VERSION ""

NS_ :

BS_:

BU_: BMS Charger

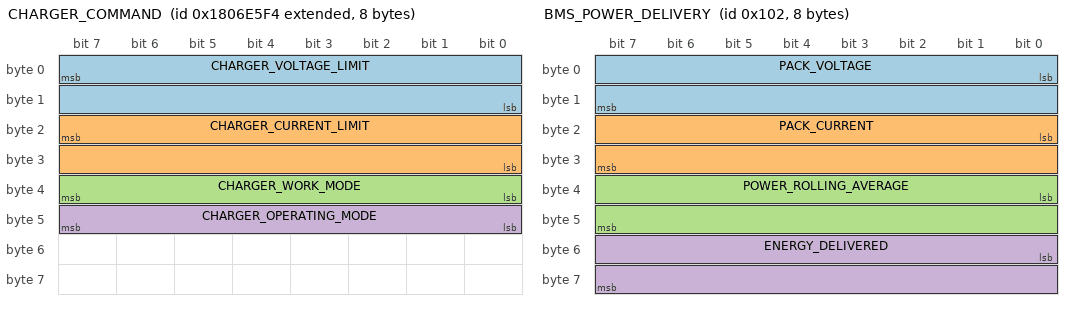
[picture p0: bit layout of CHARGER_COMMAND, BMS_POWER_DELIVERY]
BO_ 2550588916 CHARGER_COMMAND: 8 BMS
 SG_ CHARGER_VOLTAGE_LIMIT : 7|16@0+ (0.1,0) [0|680] "V" Vector__XXX
 SG_ CHARGER_CURRENT_LIMIT : 23|16@0+ (0.1,0) [0|14] "A" Vector__XXX
 SG_ CHARGER_WORK_MODE : 39|8@0+ (1,0) [0|2] "Enum" Vector__XXX
 SG_ CHARGER_OPERATING_MODE : 47|8@0+ (1,0) [0|0] "Enum" Vector__XXX

BO_ 2566869221 CHARGER_RESPONSE: 8 Charger
 SG_ CHARGE_VOLTGE_OUTPUT : 7|16@0+ (0.1,0) [0|680] "V" Vector__XXX
 SG_ CHARGER_CURRENT_OUTPUT : 23|16@0+ (0.1,0) [0|14] "A" Vector__XXX
 SG_ CHARGER_HARDWARE_PROTECTION : 32|1@0+ (1,0) [0|1] "Bool" Vector__XXX
 SG_ CHARGER_TEMPERATURE_PROTECTION : 33|1@0+ (1,0) [0|1] "Bool" Vector__XXX
 SG_ CHARGER_INPUT_VOLTAGE_STATUS : 35|2@0+ (1,0) [0|1] "Bool" Vector__XXX
 SG_ CHARGER_OUTPUT_UNDERVOLTAGE : 36|1@0+ (1,0) [0|1] "Bool" Vector__XXX
 SG_ CHARGER_OUTPUT_OVERVOLTAGE : 37|1@0+ (1,0) [0|1] "Bool" Vector__XXX
 SG_ CHARGE__OUTPUT_OVERCURRENT : 38|1@0+ (1,0) [0|1] "Bool" Vector__XXX
 SG_ CHARGER_OUTPUT_SHORT_CIRCUIT : 39|1@0+ (1,0) [0|1] "Bool" Vector__XXX
 SG_ CHARGER_COMMAND_FAULT : 40|1@0+ (1,0) [0|1] "Bool" Vector__XXX
 SG_ CHARGER_WORK_STATUS : 42|2@0+ (1,0) [0|3] "Enum" Vector__XXX
 SG_ CHARGER_INITIALIZED : 43|1@0+ (1,0) [0|1] "Bool" Vector__XXX
 SG_ CHARGER_FAN_ENABLED : 44|1@0+ (1,0) [0|1] "Bool" Vector__XXX
 SG_ CHARGER_COOLING_PUMP_ENABLED : 45|1@0+ (1,0) [0|1] "Bool" Vector__XXX
 SG_ CHARGER_CC_STATUS : 49|2@0+ (1,0) [0|3] "Enum" Vector__XXX
 SG_ CHARGER_CP_STATUS : 50|1@0+ (1,0) [0|1] "Bool" Vector__XXX
 SG_ CHARGER_SOCKET_OVERTEMPERATURE : 51|1@0+ (1,0) [0|1] "Bool" Vector__XXX
 SG_ CHARGER_ELECTRONIC_LOCK : 54|3@0+ (1,0) [0|4] "Enum" Vector__XXX
 SG_ CHARGER_S2_SWITCH_CONTROL : 55|1@0+ (1,0) [0|1] "Bool" Vector__XXX
 SG_ CHARGER_TEMPERATURE : 63|8@0+ (1,-40) [-40|205] "C" Vector__XXX

BO_ 257 BMS_STATUS: 6 BMS
 SG_ BMS_UNDERVOLTAGE_FAULT : 0|1@1+ (1,0) [0|1] "Bool" Vector__XXX
 SG_ BMS_OVERVOLTAGE_FAULT : 1|1@1+ (1,0) [0|1] "Bool" Vector__XXX
 SG_ BMS_UNDERTEMPERATURE_FAULT : 2|1@1+ (1,0) [0|1] "Bool" Vector__XXX
 SG_ BMS_OVERTEMPERATURE_FAULT : 3|1@1+ (1,0) [0|1] "Bool" Vector__XXX
 SG_ BMS_SENSE_LINE_FAULT : 4|1@1+ (1,0) [0|1] "Bool" Vector__XXX
 SG_ BMS_ISOSPI_FAULT : 5|1@1+ (1,0) [0|1] "Bool" Vector__XXX
 SG_ BMS_SELF_TEST_FAULT : 6|1@1+ (1,0) [0|1] "Bool" Vector__XXX
 SG_ BMS_LTC_0_ISOSPI_FAULT : 16|1@1+ (1,0) [0|1] "Bool" Vector__XXX
 SG_ BMS_LTC_1_ISOSPI_FAULT : 17|1@1+ (1,0) [0|1] "Bool" Vector__XXX
 SG_ BMS_LTC_2_ISOSPI_FAULT : 18|1@1+ (1,0) [0|1] "Bool" Vector__XXX
 SG_ BMS_LTC_3_ISOSPI_FAULT : 19|1@1+ (1,0) [0|1] "Bool" Vector__XXX
 SG_ BMS_LTC_4_ISOSPI_FAULT : 20|1@1+ (1,0) [0|1] "Bool" Vector__XXX
 SG_ BMS_LTC_5_ISOSPI_FAULT : 21|1@1+ (1,0) [0|1] "Bool" Vector__XXX
 SG_ BMS_LTC_6_ISOSPI_FAULT : 22|1@1+ (1,0) [0|1] "Bool" Vector__XXX
 SG_ BMS_LTC_7_ISOSPI_FAULT : 23|1@1+ (1,0) [0|1] "Bool" Vector__XXX
 SG_ BMS_LTC_8_ISOSPI_FAULT : 24|1@1+ (1,0) [0|1] "Bool" Vector__XXX
 SG_ BMS_LTC_9_ISOSPI_FAULT : 25|1@1+ (1,0) [0|1] "Bool" Vector__XXX
 SG_ BMS_LTC_10_ISOSPI_FAULT : 26|1@1+ (1,0) [0|1] "Bool" Vector__XXX
 SG_ BMS_LTC_11_ISOSPI_FAULT : 27|1@1+ (1,0) [0|1] "Bool" Vector__XXX
 SG_ BMS_LTC_0_SELF_TEST_FAULT : 32|1@1+ (1,0) [0|1] "Bool" Vector__XXX
 SG_ BMS_LTC_1_SELF_TEST_FAULT : 33|1@1+ (1,0) [0|1] "Bool" Vector__XXX
 SG_ BMS_LTC_2_SELF_TEST_FAULT : 34|1@1+ (1,0) [0|1] "Bool" Vector__XXX
 SG_ BMS_LTC_3_SELF_TEST_FAULT : 35|1@1+ (1,0) [0|1] "Bool" Vector__XXX
 SG_ BMS_LTC_4_SELF_TEST_FAULT : 36|1@1+ (1,0) [0|1] "Bool" Vector__XXX
 SG_ BMS_LTC_5_SELF_TEST_FAULT : 37|1@1+ (1,0) [0|1] "Bool" Vector__XXX
 SG_ BMS_LTC_6_SELF_TEST_FAULT : 38|1@1+ (1,0) [0|1] "Bool" Vector__XXX
 SG_ BMS_LTC_7_SELF_TEST_FAULT : 39|1@1+ (1,0) [0|1] "Bool" Vector__XXX
 SG_ BMS_LTC_8_SELF_TEST_FAULT : 40|1@1+ (1,0) [0|1] "Bool" Vector__XXX
 SG_ BMS_LTC_9_SELF_TEST_FAULT : 41|1@1+ (1,0) [0|1] "Bool" Vector__XXX
 SG_ BMS_LTC_10_SELF_TEST_FAULT : 42|1@1+ (1,0) [0|1] "Bool" Vector__XXX
 SG_ BMS_LTC_11_SELF_TEST_FAULT : 43|1@1+ (1,0) [0|1] "Bool" Vector__XXX
 SG_ BMS_CHARGING : 7|1@1+ (1,0) [0|1] "Bool" Vector__XXX
 SG_ BMS_BALANCING : 8|1@1+ (1,0) [0|1] "Bool" Vector__XXX
 SG_ SHUTDOWN_CLOSED : 9|1@1+ (1,0) [0|1] "Bool" Vector__XXX
 SG_ PRECHARGE_COMPLETE : 10|1@1+ (1,0) [0|1] "Bool" Vector__XXX
 SG_ SHUTDOWN_LOOP_BLIP : 11|1@1+ (1,0) [0|1] "Bool" Vector__XXX
 SG_ BMS_RELAY_STATUS : 12|1@1+ (1,0) [0|1] "Bool" Vector__XXX
 SG_ IMD_RELAY_STATUS : 13|1@1+ (1,0) [0|1] "Bool" Vector__XXX
 SG_ BMS_FAULT : 14|1@1+ (1,0) [0|0] "Bool" Vector__XXX

BO_ 258 BMS_POWER_DELIVERY: 8 BMS
 SG_ PACK_VOLTAGE : 0|16@1+ (0.0125,0) [0|819.2] "V" Vector__XXX
 SG_ PACK_CURRENT : 16|16@1- (0.019073486328125,0) [-625|625] "A" Vector__XXX
 SG_ POWER_ROLLING_AVERAGE : 32|16@1- (0.004,0) [-131.072|131.068] "kW" Vector__XXX
 SG_ ENERGY_DELIVERED : 48|16@1- (0.0005,0) [-16.384|16.3835] "kWh" Vector__XXX

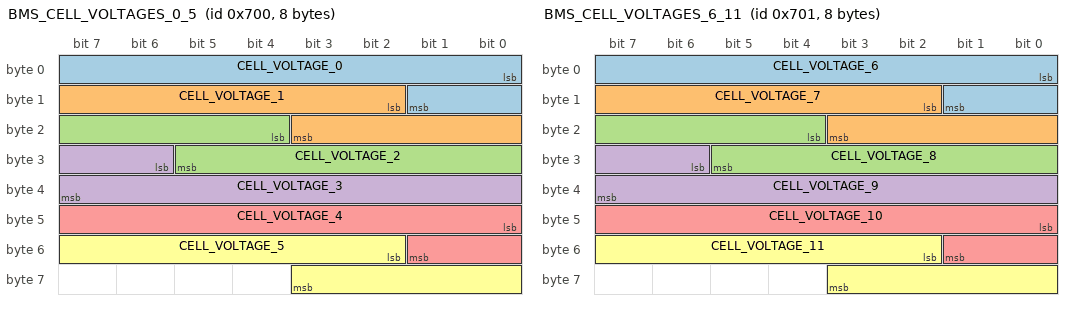
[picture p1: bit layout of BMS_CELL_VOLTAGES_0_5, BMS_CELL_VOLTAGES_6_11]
BO_ 1792 BMS_CELL_VOLTAGES_0_5: 8 BMS
 SG_ CELL_VOLTAGE_0 : 0|10@1+ (0.0078125,0) [0|8] "V" Vector__XXX
 SG_ CELL_VOLTAGE_1 : 10|10@1+ (0.0078125,0) [0|8] "V" Vector__XXX
 SG_ CELL_VOLTAGE_2 : 20|10@1+ (0.0078125,0) [0|8] "V" Vector__XXX
 SG_ CELL_VOLTAGE_3 : 30|10@1+ (0.0078125,0) [0|8] "V" Vector__XXX
 SG_ CELL_VOLTAGE_4 : 40|10@1+ (0.0078125,0) [0|8] "V" Vector__XXX
 SG_ CELL_VOLTAGE_5 : 50|10@1+ (0.0078125,0) [0|8] "V" Vector__XXX

BO_ 1793 BMS_CELL_VOLTAGES_6_11: 8 BMS
 SG_ CELL_VOLTAGE_6 : 0|10@1+ (0.0078125,0) [0|8] "V" Vector__XXX
 SG_ CELL_VOLTAGE_7 : 10|10@1+ (0.0078125,0) [0|8] "V" Vector__XXX
 SG_ CELL_VOLTAGE_8 : 20|10@1+ (0.0078125,0) [0|8] "V" Vector__XXX
 SG_ CELL_VOLTAGE_9 : 30|10@1+ (0.0078125,0) [0|8] "V" Vector__XXX
 SG_ CELL_VOLTAGE_10 : 40|10@1+ (0.0078125,0) [0|8] "V" Vector__XXX
 SG_ CELL_VOLTAGE_11 : 50|10@1+ (0.0078125,0) [0|8] "V" Vector__XXX

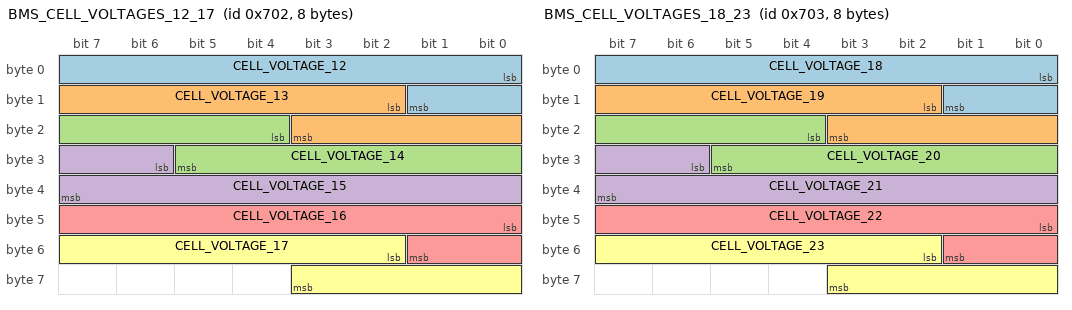
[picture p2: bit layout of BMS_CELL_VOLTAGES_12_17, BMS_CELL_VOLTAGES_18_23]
BO_ 1794 BMS_CELL_VOLTAGES_12_17: 8 BMS
 SG_ CELL_VOLTAGE_12 : 0|10@1+ (0.0078125,0) [0|8] "V" Vector__XXX
 SG_ CELL_VOLTAGE_13 : 10|10@1+ (0.0078125,0) [0|8] "V" Vector__XXX
 SG_ CELL_VOLTAGE_14 : 20|10@1+ (0.0078125,0) [0|8] "V" Vector__XXX
 SG_ CELL_VOLTAGE_15 : 30|10@1+ (0.0078125,0) [0|8] "V" Vector__XXX
 SG_ CELL_VOLTAGE_16 : 40|10@1+ (0.0078125,0) [0|8] "V" Vector__XXX
 SG_ CELL_VOLTAGE_17 : 50|10@1+ (0.0078125,0) [0|8] "V" Vector__XXX

BO_ 1795 BMS_CELL_VOLTAGES_18_23: 8 BMS
 SG_ CELL_VOLTAGE_18 : 0|10@1+ (0.0078125,0) [0|8] "V" Vector__XXX
 SG_ CELL_VOLTAGE_19 : 10|10@1+ (0.0078125,0) [0|8] "V" Vector__XXX
 SG_ CELL_VOLTAGE_20 : 20|10@1+ (0.0078125,0) [0|8] "V" Vector__XXX
 SG_ CELL_VOLTAGE_21 : 30|10@1+ (0.0078125,0) [0|8] "V" Vector__XXX
 SG_ CELL_VOLTAGE_22 : 40|10@1+ (0.0078125,0) [0|8] "V" Vector__XXX
 SG_ CELL_VOLTAGE_23 : 50|10@1+ (0.0078125,0) [0|8] "V" Vector__XXX

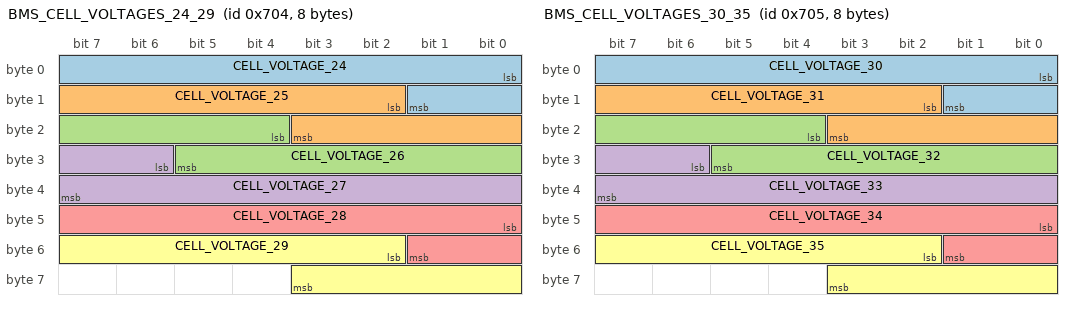
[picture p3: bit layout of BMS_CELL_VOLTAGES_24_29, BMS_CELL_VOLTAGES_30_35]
BO_ 1796 BMS_CELL_VOLTAGES_24_29: 8 BMS
 SG_ CELL_VOLTAGE_24 : 0|10@1+ (0.0078125,0) [0|8] "V" Vector__XXX
 SG_ CELL_VOLTAGE_25 : 10|10@1+ (0.0078125,0) [0|8] "V" Vector__XXX
 SG_ CELL_VOLTAGE_26 : 20|10@1+ (0.0078125,0) [0|8] "V" Vector__XXX
 SG_ CELL_VOLTAGE_27 : 30|10@1+ (0.0078125,0) [0|8] "V" Vector__XXX
 SG_ CELL_VOLTAGE_28 : 40|10@1+ (0.0078125,0) [0|8] "V" Vector__XXX
 SG_ CELL_VOLTAGE_29 : 50|10@1+ (0.0078125,0) [0|8] "V" Vector__XXX

BO_ 1797 BMS_CELL_VOLTAGES_30_35: 8 BMS
 SG_ CELL_VOLTAGE_30 : 0|10@1+ (0.0078125,0) [0|8] "V" Vector__XXX
 SG_ CELL_VOLTAGE_31 : 10|10@1+ (0.0078125,0) [0|8] "V" Vector__XXX
 SG_ CELL_VOLTAGE_32 : 20|10@1+ (0.0078125,0) [0|8] "V" Vector__XXX
 SG_ CELL_VOLTAGE_33 : 30|10@1+ (0.0078125,0) [0|8] "V" Vector__XXX
 SG_ CELL_VOLTAGE_34 : 40|10@1+ (0.0078125,0) [0|8] "V" Vector__XXX
 SG_ CELL_VOLTAGE_35 : 50|10@1+ (0.0078125,0) [0|8] "V" Vector__XXX

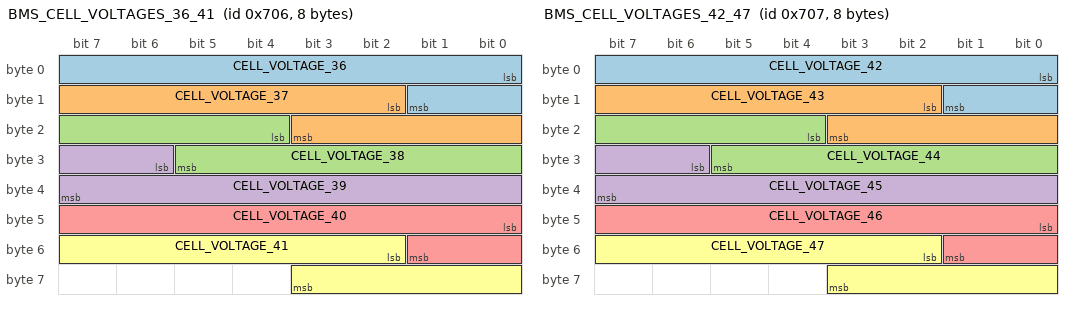
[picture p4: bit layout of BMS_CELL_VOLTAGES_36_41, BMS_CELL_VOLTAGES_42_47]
BO_ 1798 BMS_CELL_VOLTAGES_36_41: 8 BMS
 SG_ CELL_VOLTAGE_36 : 0|10@1+ (0.0078125,0) [0|8] "V" Vector__XXX
 SG_ CELL_VOLTAGE_37 : 10|10@1+ (0.0078125,0) [0|8] "V" Vector__XXX
 SG_ CELL_VOLTAGE_38 : 20|10@1+ (0.0078125,0) [0|8] "V" Vector__XXX
 SG_ CELL_VOLTAGE_39 : 30|10@1+ (0.0078125,0) [0|8] "V" Vector__XXX
 SG_ CELL_VOLTAGE_40 : 40|10@1+ (0.0078125,0) [0|8] "V" Vector__XXX
 SG_ CELL_VOLTAGE_41 : 50|10@1+ (0.0078125,0) [0|8] "V" Vector__XXX

BO_ 1799 BMS_CELL_VOLTAGES_42_47: 8 BMS
 SG_ CELL_VOLTAGE_42 : 0|10@1+ (0.0078125,0) [0|8] "V" Vector__XXX
 SG_ CELL_VOLTAGE_43 : 10|10@1+ (0.0078125,0) [0|8] "V" Vector__XXX
 SG_ CELL_VOLTAGE_44 : 20|10@1+ (0.0078125,0) [0|8] "V" Vector__XXX
 SG_ CELL_VOLTAGE_45 : 30|10@1+ (0.0078125,0) [0|8] "V" Vector__XXX
 SG_ CELL_VOLTAGE_46 : 40|10@1+ (0.0078125,0) [0|8] "V" Vector__XXX
 SG_ CELL_VOLTAGE_47 : 50|10@1+ (0.0078125,0) [0|8] "V" Vector__XXX

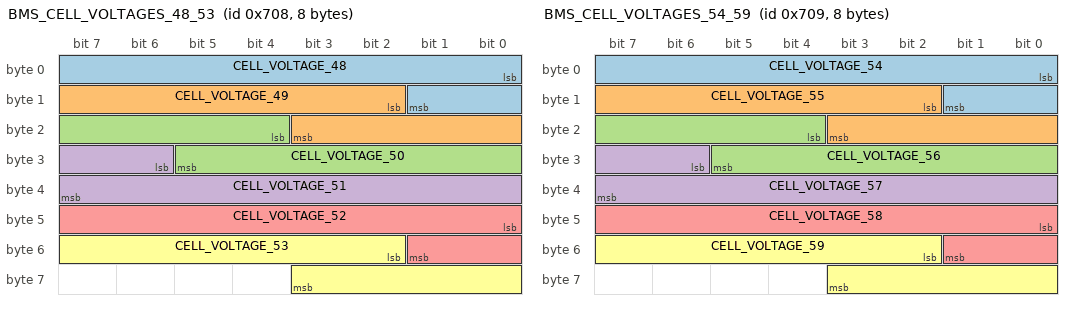
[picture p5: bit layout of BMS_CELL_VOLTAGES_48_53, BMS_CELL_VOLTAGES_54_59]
BO_ 1800 BMS_CELL_VOLTAGES_48_53: 8 BMS
 SG_ CELL_VOLTAGE_48 : 0|10@1+ (0.0078125,0) [0|8] "V" Vector__XXX
 SG_ CELL_VOLTAGE_49 : 10|10@1+ (0.0078125,0) [0|8] "V" Vector__XXX
 SG_ CELL_VOLTAGE_50 : 20|10@1+ (0.0078125,0) [0|8] "V" Vector__XXX
 SG_ CELL_VOLTAGE_51 : 30|10@1+ (0.0078125,0) [0|8] "V" Vector__XXX
 SG_ CELL_VOLTAGE_52 : 40|10@1+ (0.0078125,0) [0|8] "V" Vector__XXX
 SG_ CELL_VOLTAGE_53 : 50|10@1+ (0.0078125,0) [0|8] "V" Vector__XXX

BO_ 1801 BMS_CELL_VOLTAGES_54_59: 8 BMS
 SG_ CELL_VOLTAGE_54 : 0|10@1+ (0.0078125,0) [0|8] "V" Vector__XXX
 SG_ CELL_VOLTAGE_55 : 10|10@1+ (0.0078125,0) [0|8] "V" Vector__XXX
 SG_ CELL_VOLTAGE_56 : 20|10@1+ (0.0078125,0) [0|8] "V" Vector__XXX
 SG_ CELL_VOLTAGE_57 : 30|10@1+ (0.0078125,0) [0|8] "V" Vector__XXX
 SG_ CELL_VOLTAGE_58 : 40|10@1+ (0.0078125,0) [0|8] "V" Vector__XXX
 SG_ CELL_VOLTAGE_59 : 50|10@1+ (0.0078125,0) [0|8] "V" Vector__XXX

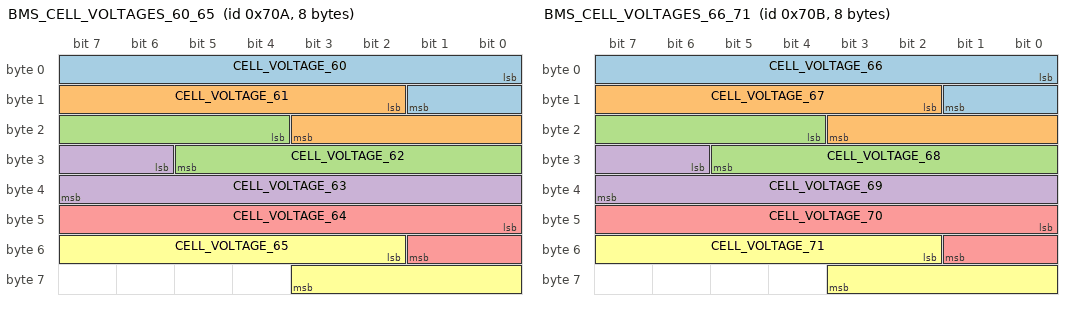
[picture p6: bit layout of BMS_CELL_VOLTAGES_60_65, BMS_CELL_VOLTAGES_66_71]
BO_ 1802 BMS_CELL_VOLTAGES_60_65: 8 BMS
 SG_ CELL_VOLTAGE_60 : 0|10@1+ (0.0078125,0) [0|8] "V" Vector__XXX
 SG_ CELL_VOLTAGE_61 : 10|10@1+ (0.0078125,0) [0|8] "V" Vector__XXX
 SG_ CELL_VOLTAGE_62 : 20|10@1+ (0.0078125,0) [0|8] "V" Vector__XXX
 SG_ CELL_VOLTAGE_63 : 30|10@1+ (0.0078125,0) [0|8] "V" Vector__XXX
 SG_ CELL_VOLTAGE_64 : 40|10@1+ (0.0078125,0) [0|8] "V" Vector__XXX
 SG_ CELL_VOLTAGE_65 : 50|10@1+ (0.0078125,0) [0|8] "V" Vector__XXX

BO_ 1803 BMS_CELL_VOLTAGES_66_71: 8 BMS
 SG_ CELL_VOLTAGE_66 : 0|10@1+ (0.0078125,0) [0|8] "V" Vector__XXX
 SG_ CELL_VOLTAGE_67 : 10|10@1+ (0.0078125,0) [0|8] "V" Vector__XXX
 SG_ CELL_VOLTAGE_68 : 20|10@1+ (0.0078125,0) [0|8] "V" Vector__XXX
 SG_ CELL_VOLTAGE_69 : 30|10@1+ (0.0078125,0) [0|8] "V" Vector__XXX
 SG_ CELL_VOLTAGE_70 : 40|10@1+ (0.0078125,0) [0|8] "V" Vector__XXX
 SG_ CELL_VOLTAGE_71 : 50|10@1+ (0.0078125,0) [0|8] "V" Vector__XXX

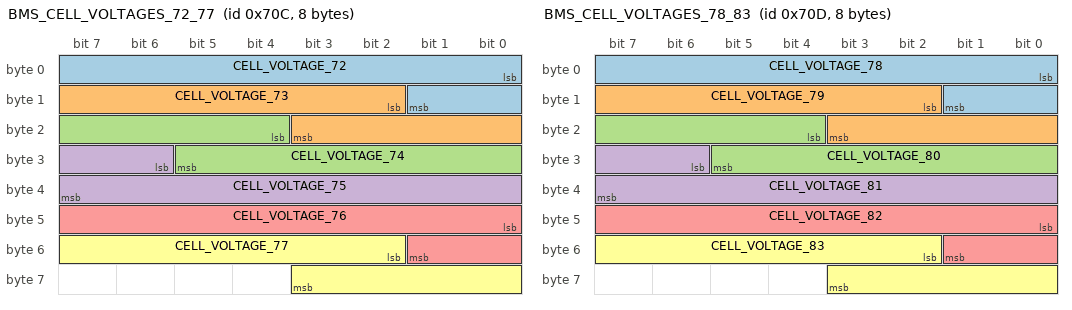
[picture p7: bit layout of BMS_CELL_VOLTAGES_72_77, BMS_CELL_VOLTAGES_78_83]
BO_ 1804 BMS_CELL_VOLTAGES_72_77: 8 BMS
 SG_ CELL_VOLTAGE_72 : 0|10@1+ (0.0078125,0) [0|8] "V" Vector__XXX
 SG_ CELL_VOLTAGE_73 : 10|10@1+ (0.0078125,0) [0|8] "V" Vector__XXX
 SG_ CELL_VOLTAGE_74 : 20|10@1+ (0.0078125,0) [0|8] "V" Vector__XXX
 SG_ CELL_VOLTAGE_75 : 30|10@1+ (0.0078125,0) [0|8] "V" Vector__XXX
 SG_ CELL_VOLTAGE_76 : 40|10@1+ (0.0078125,0) [0|8] "V" Vector__XXX
 SG_ CELL_VOLTAGE_77 : 50|10@1+ (0.0078125,0) [0|8] "V" Vector__XXX

BO_ 1805 BMS_CELL_VOLTAGES_78_83: 8 BMS
 SG_ CELL_VOLTAGE_78 : 0|10@1+ (0.0078125,0) [0|8] "V" Vector__XXX
 SG_ CELL_VOLTAGE_79 : 10|10@1+ (0.0078125,0) [0|8] "V" Vector__XXX
 SG_ CELL_VOLTAGE_80 : 20|10@1+ (0.0078125,0) [0|8] "V" Vector__XXX
 SG_ CELL_VOLTAGE_81 : 30|10@1+ (0.0078125,0) [0|8] "V" Vector__XXX
 SG_ CELL_VOLTAGE_82 : 40|10@1+ (0.0078125,0) [0|8] "V" Vector__XXX
 SG_ CELL_VOLTAGE_83 : 50|10@1+ (0.0078125,0) [0|8] "V" Vector__XXX

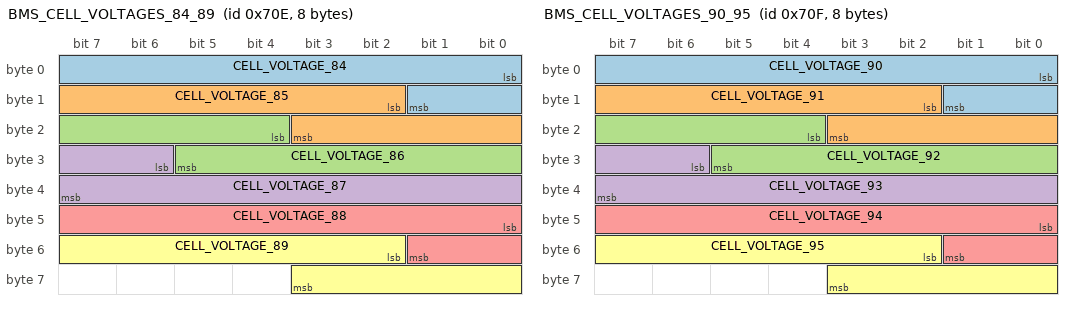
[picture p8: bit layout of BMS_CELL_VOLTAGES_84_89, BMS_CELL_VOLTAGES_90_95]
BO_ 1806 BMS_CELL_VOLTAGES_84_89: 8 BMS
 SG_ CELL_VOLTAGE_84 : 0|10@1+ (0.0078125,0) [0|8] "V" Vector__XXX
 SG_ CELL_VOLTAGE_85 : 10|10@1+ (0.0078125,0) [0|8] "V" Vector__XXX
 SG_ CELL_VOLTAGE_86 : 20|10@1+ (0.0078125,0) [0|8] "V" Vector__XXX
 SG_ CELL_VOLTAGE_87 : 30|10@1+ (0.0078125,0) [0|8] "V" Vector__XXX
 SG_ CELL_VOLTAGE_88 : 40|10@1+ (0.0078125,0) [0|8] "V" Vector__XXX
 SG_ CELL_VOLTAGE_89 : 50|10@1+ (0.0078125,0) [0|8] "V" Vector__XXX

BO_ 1807 BMS_CELL_VOLTAGES_90_95: 8 BMS
 SG_ CELL_VOLTAGE_90 : 0|10@1+ (0.0078125,0) [0|8] "V" Vector__XXX
 SG_ CELL_VOLTAGE_91 : 10|10@1+ (0.0078125,0) [0|8] "V" Vector__XXX
 SG_ CELL_VOLTAGE_92 : 20|10@1+ (0.0078125,0) [0|8] "V" Vector__XXX
 SG_ CELL_VOLTAGE_93 : 30|10@1+ (0.0078125,0) [0|8] "V" Vector__XXX
 SG_ CELL_VOLTAGE_94 : 40|10@1+ (0.0078125,0) [0|8] "V" Vector__XXX
 SG_ CELL_VOLTAGE_95 : 50|10@1+ (0.0078125,0) [0|8] "V" Vector__XXX

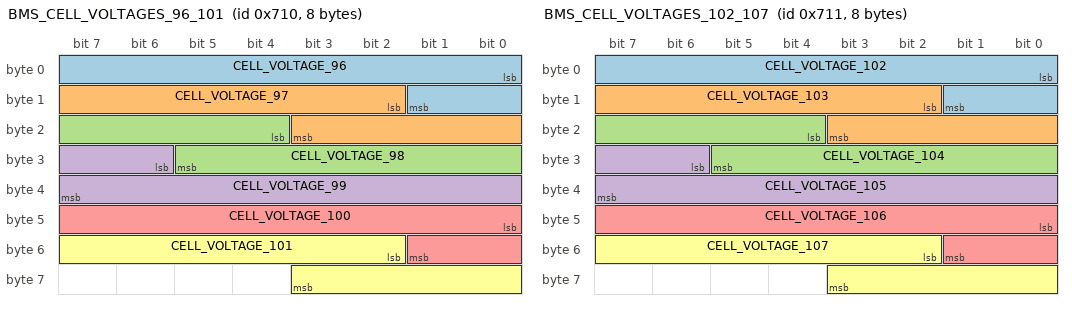
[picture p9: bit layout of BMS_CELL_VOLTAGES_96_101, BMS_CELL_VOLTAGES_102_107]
BO_ 1808 BMS_CELL_VOLTAGES_96_101: 8 BMS
 SG_ CELL_VOLTAGE_96 : 0|10@1+ (0.0078125,0) [0|8] "V" Vector__XXX
 SG_ CELL_VOLTAGE_97 : 10|10@1+ (0.0078125,0) [0|8] "V" Vector__XXX
 SG_ CELL_VOLTAGE_98 : 20|10@1+ (0.0078125,0) [0|8] "V" Vector__XXX
 SG_ CELL_VOLTAGE_99 : 30|10@1+ (0.0078125,0) [0|8] "V" Vector__XXX
 SG_ CELL_VOLTAGE_100 : 40|10@1+ (0.0078125,0) [0|8] "V" Vector__XXX
 SG_ CELL_VOLTAGE_101 : 50|10@1+ (0.0078125,0) [0|8] "V" Vector__XXX

BO_ 1809 BMS_CELL_VOLTAGES_102_107: 8 BMS
 SG_ CELL_VOLTAGE_102 : 0|10@1+ (0.0078125,0) [0|8] "V" Vector__XXX
 SG_ CELL_VOLTAGE_103 : 10|10@1+ (0.0078125,0) [0|8] "V" Vector__XXX
 SG_ CELL_VOLTAGE_104 : 20|10@1+ (0.0078125,0) [0|8] "V" Vector__XXX
 SG_ CELL_VOLTAGE_105 : 30|10@1+ (0.0078125,0) [0|8] "V" Vector__XXX
 SG_ CELL_VOLTAGE_106 : 40|10@1+ (0.0078125,0) [0|8] "V" Vector__XXX
 SG_ CELL_VOLTAGE_107 : 50|10@1+ (0.0078125,0) [0|8] "V" Vector__XXX

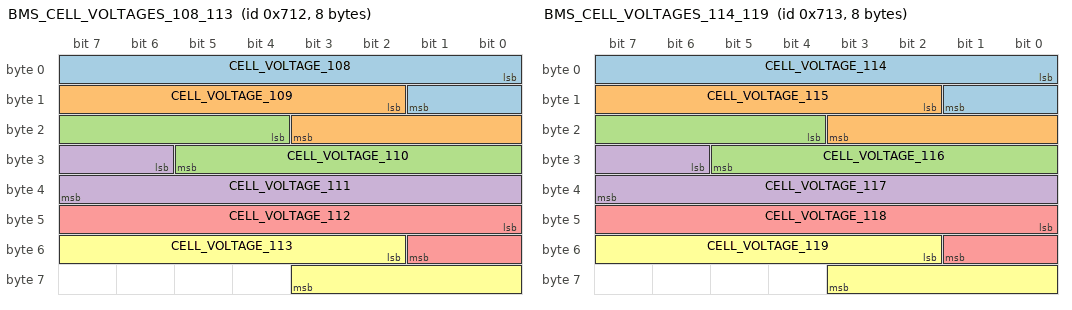
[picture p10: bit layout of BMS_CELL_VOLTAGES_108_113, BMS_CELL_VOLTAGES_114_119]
BO_ 1810 BMS_CELL_VOLTAGES_108_113: 8 BMS
 SG_ CELL_VOLTAGE_108 : 0|10@1+ (0.0078125,0) [0|8] "V" Vector__XXX
 SG_ CELL_VOLTAGE_109 : 10|10@1+ (0.0078125,0) [0|8] "V" Vector__XXX
 SG_ CELL_VOLTAGE_110 : 20|10@1+ (0.0078125,0) [0|8] "V" Vector__XXX
 SG_ CELL_VOLTAGE_111 : 30|10@1+ (0.0078125,0) [0|8] "V" Vector__XXX
 SG_ CELL_VOLTAGE_112 : 40|10@1+ (0.0078125,0) [0|8] "V" Vector__XXX
 SG_ CELL_VOLTAGE_113 : 50|10@1+ (0.0078125,0) [0|8] "V" Vector__XXX

BO_ 1811 BMS_CELL_VOLTAGES_114_119: 8 BMS
 SG_ CELL_VOLTAGE_114 : 0|10@1+ (0.0078125,0) [0|8] "V" Vector__XXX
 SG_ CELL_VOLTAGE_115 : 10|10@1+ (0.0078125,0) [0|8] "V" Vector__XXX
 SG_ CELL_VOLTAGE_116 : 20|10@1+ (0.0078125,0) [0|8] "V" Vector__XXX
 SG_ CELL_VOLTAGE_117 : 30|10@1+ (0.0078125,0) [0|8] "V" Vector__XXX
 SG_ CELL_VOLTAGE_118 : 40|10@1+ (0.0078125,0) [0|8] "V" Vector__XXX
 SG_ CELL_VOLTAGE_119 : 50|10@1+ (0.0078125,0) [0|8] "V" Vector__XXX

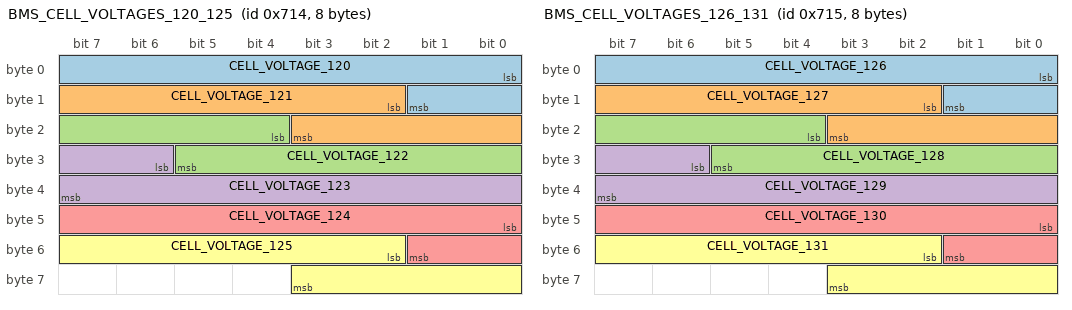
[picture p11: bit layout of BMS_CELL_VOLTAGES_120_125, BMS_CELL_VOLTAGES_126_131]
BO_ 1812 BMS_CELL_VOLTAGES_120_125: 8 BMS
 SG_ CELL_VOLTAGE_120 : 0|10@1+ (0.0078125,0) [0|8] "V" Vector__XXX
 SG_ CELL_VOLTAGE_121 : 10|10@1+ (0.0078125,0) [0|8] "V" Vector__XXX
 SG_ CELL_VOLTAGE_122 : 20|10@1+ (0.0078125,0) [0|8] "V" Vector__XXX
 SG_ CELL_VOLTAGE_123 : 30|10@1+ (0.0078125,0) [0|8] "V" Vector__XXX
 SG_ CELL_VOLTAGE_124 : 40|10@1+ (0.0078125,0) [0|8] "V" Vector__XXX
 SG_ CELL_VOLTAGE_125 : 50|10@1+ (0.0078125,0) [0|8] "V" Vector__XXX

BO_ 1813 BMS_CELL_VOLTAGES_126_131: 8 BMS
 SG_ CELL_VOLTAGE_126 : 0|10@1+ (0.0078125,0) [0|8] "V" Vector__XXX
 SG_ CELL_VOLTAGE_127 : 10|10@1+ (0.0078125,0) [0|8] "V" Vector__XXX
 SG_ CELL_VOLTAGE_128 : 20|10@1+ (0.0078125,0) [0|8] "V" Vector__XXX
 SG_ CELL_VOLTAGE_129 : 30|10@1+ (0.0078125,0) [0|8] "V" Vector__XXX
 SG_ CELL_VOLTAGE_130 : 40|10@1+ (0.0078125,0) [0|8] "V" Vector__XXX
 SG_ CELL_VOLTAGE_131 : 50|10@1+ (0.0078125,0) [0|8] "V" Vector__XXX

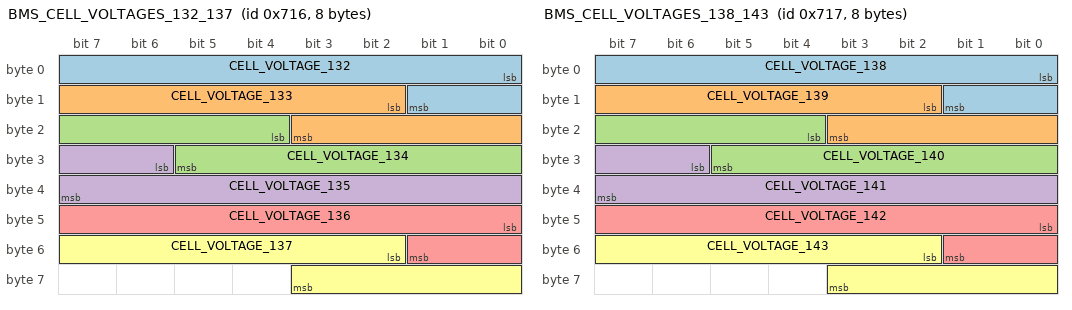
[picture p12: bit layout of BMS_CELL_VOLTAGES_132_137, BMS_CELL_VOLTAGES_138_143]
BO_ 1814 BMS_CELL_VOLTAGES_132_137: 8 BMS
 SG_ CELL_VOLTAGE_132 : 0|10@1+ (0.0078125,0) [0|8] "V" Vector__XXX
 SG_ CELL_VOLTAGE_133 : 10|10@1+ (0.0078125,0) [0|8] "V" Vector__XXX
 SG_ CELL_VOLTAGE_134 : 20|10@1+ (0.0078125,0) [0|8] "V" Vector__XXX
 SG_ CELL_VOLTAGE_135 : 30|10@1+ (0.0078125,0) [0|8] "V" Vector__XXX
 SG_ CELL_VOLTAGE_136 : 40|10@1+ (0.0078125,0) [0|8] "V" Vector__XXX
 SG_ CELL_VOLTAGE_137 : 50|10@1+ (0.0078125,0) [0|8] "V" Vector__XXX

BO_ 1815 BMS_CELL_VOLTAGES_138_143: 8 BMS
 SG_ CELL_VOLTAGE_138 : 0|10@1+ (0.0078125,0) [0|8] "V" Vector__XXX
 SG_ CELL_VOLTAGE_139 : 10|10@1+ (0.0078125,0) [0|8] "V" Vector__XXX
 SG_ CELL_VOLTAGE_140 : 20|10@1+ (0.0078125,0) [0|8] "V" Vector__XXX
 SG_ CELL_VOLTAGE_141 : 30|10@1+ (0.0078125,0) [0|8] "V" Vector__XXX
 SG_ CELL_VOLTAGE_142 : 40|10@1+ (0.0078125,0) [0|8] "V" Vector__XXX
 SG_ CELL_VOLTAGE_143 : 50|10@1+ (0.0078125,0) [0|8] "V" Vector__XXX

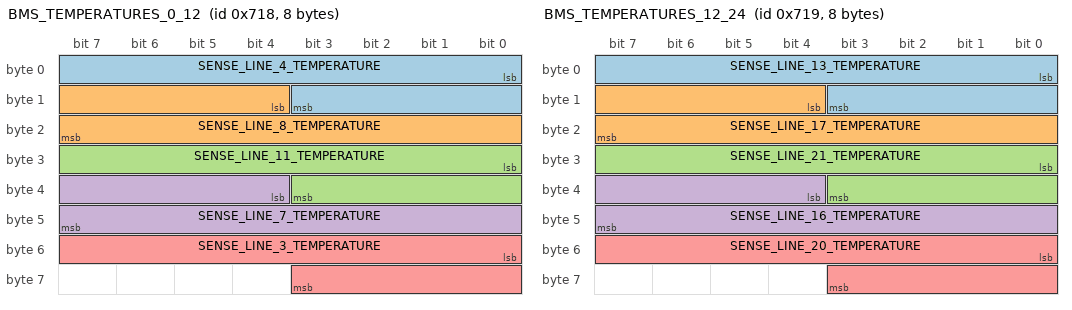
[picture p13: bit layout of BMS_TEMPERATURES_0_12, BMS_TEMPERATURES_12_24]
BO_ 1816 BMS_TEMPERATURES_0_12: 8 BMS
 SG_ SENSE_LINE_4_TEMPERATURE : 0|12@1+ (0.0625,-106) [-106|150] "C" Vector__XXX
 SG_ SENSE_LINE_8_TEMPERATURE : 12|12@1+ (0.0625,-106) [-106|150] "C" Vector__XXX
 SG_ SENSE_LINE_11_TEMPERATURE : 24|12@1+ (0.0625,-106) [-106|150] "C" Vector__XXX
 SG_ SENSE_LINE_7_TEMPERATURE : 36|12@1+ (0.0625,-106) [-106|150] "C" Vector__XXX
 SG_ SENSE_LINE_3_TEMPERATURE : 48|12@1+ (0.0625,-106) [-106|150] "C" Vector__XXX

BO_ 1817 BMS_TEMPERATURES_12_24: 8 BMS
 SG_ SENSE_LINE_13_TEMPERATURE : 0|12@1+ (0.0625,-106) [-106|150] "C" Vector__XXX
 SG_ SENSE_LINE_17_TEMPERATURE : 12|12@1+ (0.0625,-106) [-106|150] "C" Vector__XXX
 SG_ SENSE_LINE_21_TEMPERATURE : 24|12@1+ (0.0625,-106) [-106|150] "C" Vector__XXX
 SG_ SENSE_LINE_16_TEMPERATURE : 36|12@1+ (0.0625,-106) [-106|150] "C" Vector__XXX
 SG_ SENSE_LINE_20_TEMPERATURE : 48|12@1+ (0.0625,-106) [-106|150] "C" Vector__XXX

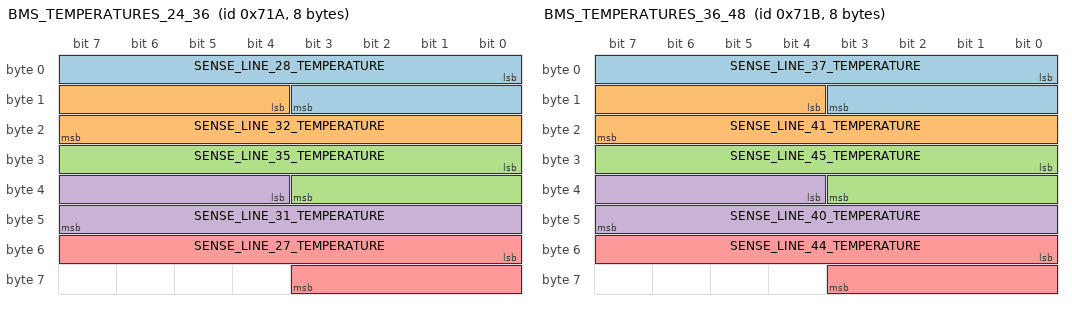
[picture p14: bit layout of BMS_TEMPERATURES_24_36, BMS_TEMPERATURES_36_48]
BO_ 1818 BMS_TEMPERATURES_24_36: 8 BMS
 SG_ SENSE_LINE_28_TEMPERATURE : 0|12@1+ (0.0625,-106) [-106|150] "C" Vector__XXX
 SG_ SENSE_LINE_32_TEMPERATURE : 12|12@1+ (0.0625,-106) [-106|150] "C" Vector__XXX
 SG_ SENSE_LINE_35_TEMPERATURE : 24|12@1+ (0.0625,-106) [-106|150] "C" Vector__XXX
 SG_ SENSE_LINE_31_TEMPERATURE : 36|12@1+ (0.0625,-106) [-106|150] "C" Vector__XXX
 SG_ SENSE_LINE_27_TEMPERATURE : 48|12@1+ (0.0625,-106) [-106|150] "C" Vector__XXX

BO_ 1819 BMS_TEMPERATURES_36_48: 8 BMS
 SG_ SENSE_LINE_37_TEMPERATURE : 0|12@1+ (0.0625,-106) [-106|150] "C" Vector__XXX
 SG_ SENSE_LINE_41_TEMPERATURE : 12|12@1+ (0.0625,-106) [-106|150] "C" Vector__XXX
 SG_ SENSE_LINE_45_TEMPERATURE : 24|12@1+ (0.0625,-106) [-106|150] "C" Vector__XXX
 SG_ SENSE_LINE_40_TEMPERATURE : 36|12@1+ (0.0625,-106) [-106|150] "C" Vector__XXX
 SG_ SENSE_LINE_44_TEMPERATURE : 48|12@1+ (0.0625,-106) [-106|150] "C" Vector__XXX

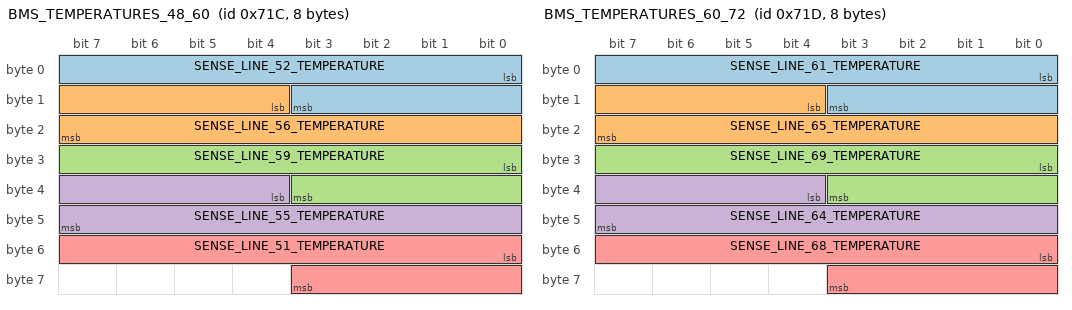
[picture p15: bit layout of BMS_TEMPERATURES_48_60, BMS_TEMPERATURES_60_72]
BO_ 1820 BMS_TEMPERATURES_48_60: 8 BMS
 SG_ SENSE_LINE_52_TEMPERATURE : 0|12@1+ (0.0625,-106) [-106|150] "C" Vector__XXX
 SG_ SENSE_LINE_56_TEMPERATURE : 12|12@1+ (0.0625,-106) [-106|150] "C" Vector__XXX
 SG_ SENSE_LINE_59_TEMPERATURE : 24|12@1+ (0.0625,-106) [-106|150] "C" Vector__XXX
 SG_ SENSE_LINE_55_TEMPERATURE : 36|12@1+ (0.0625,-106) [-106|150] "C" Vector__XXX
 SG_ SENSE_LINE_51_TEMPERATURE : 48|12@1+ (0.0625,-106) [-106|150] "C" Vector__XXX

BO_ 1821 BMS_TEMPERATURES_60_72: 8 BMS
 SG_ SENSE_LINE_61_TEMPERATURE : 0|12@1+ (0.0625,-106) [-106|150] "C" Vector__XXX
 SG_ SENSE_LINE_65_TEMPERATURE : 12|12@1+ (0.0625,-106) [-106|150] "C" Vector__XXX
 SG_ SENSE_LINE_69_TEMPERATURE : 24|12@1+ (0.0625,-106) [-106|150] "C" Vector__XXX
 SG_ SENSE_LINE_64_TEMPERATURE : 36|12@1+ (0.0625,-106) [-106|150] "C" Vector__XXX
 SG_ SENSE_LINE_68_TEMPERATURE : 48|12@1+ (0.0625,-106) [-106|150] "C" Vector__XXX

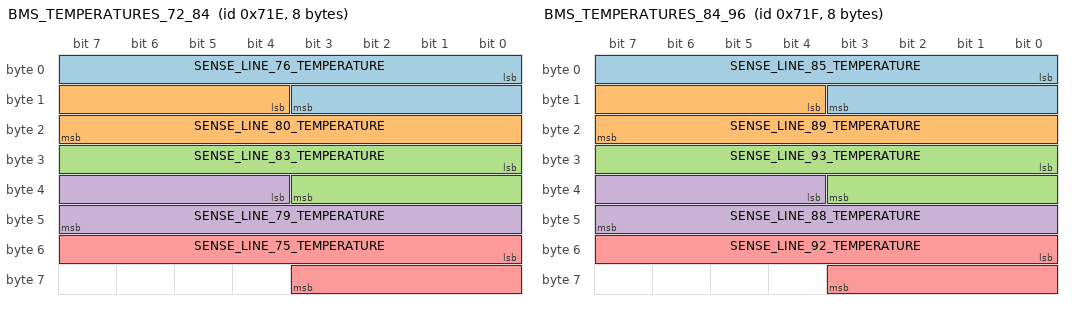
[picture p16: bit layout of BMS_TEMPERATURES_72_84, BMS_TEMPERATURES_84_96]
BO_ 1822 BMS_TEMPERATURES_72_84: 8 BMS
 SG_ SENSE_LINE_76_TEMPERATURE : 0|12@1+ (0.0625,-106) [-106|150] "C" Vector__XXX
 SG_ SENSE_LINE_80_TEMPERATURE : 12|12@1+ (0.0625,-106) [-106|150] "C" Vector__XXX
 SG_ SENSE_LINE_83_TEMPERATURE : 24|12@1+ (0.0625,-106) [-106|150] "C" Vector__XXX
 SG_ SENSE_LINE_79_TEMPERATURE : 36|12@1+ (0.0625,-106) [-106|150] "C" Vector__XXX
 SG_ SENSE_LINE_75_TEMPERATURE : 48|12@1+ (0.0625,-106) [-106|150] "C" Vector__XXX

BO_ 1823 BMS_TEMPERATURES_84_96: 8 BMS
 SG_ SENSE_LINE_85_TEMPERATURE : 0|12@1+ (0.0625,-106) [-106|150] "C" Vector__XXX
 SG_ SENSE_LINE_89_TEMPERATURE : 12|12@1+ (0.0625,-106) [-106|150] "C" Vector__XXX
 SG_ SENSE_LINE_93_TEMPERATURE : 24|12@1+ (0.0625,-106) [-106|150] "C" Vector__XXX
 SG_ SENSE_LINE_88_TEMPERATURE : 36|12@1+ (0.0625,-106) [-106|150] "C" Vector__XXX
 SG_ SENSE_LINE_92_TEMPERATURE : 48|12@1+ (0.0625,-106) [-106|150] "C" Vector__XXX

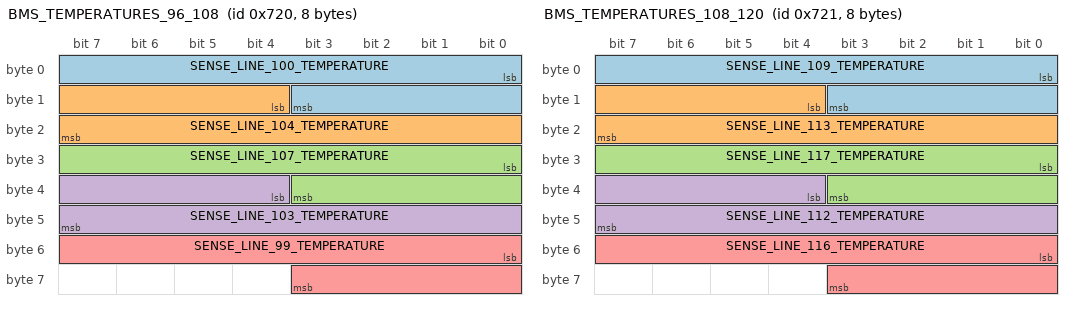
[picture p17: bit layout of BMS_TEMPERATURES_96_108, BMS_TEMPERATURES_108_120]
BO_ 1824 BMS_TEMPERATURES_96_108: 8 BMS
 SG_ SENSE_LINE_100_TEMPERATURE : 0|12@1+ (0.0625,-106) [-106|150] "C" Vector__XXX
 SG_ SENSE_LINE_104_TEMPERATURE : 12|12@1+ (0.0625,-106) [-106|150] "C" Vector__XXX
 SG_ SENSE_LINE_107_TEMPERATURE : 24|12@1+ (0.0625,-106) [-106|150] "C" Vector__XXX
 SG_ SENSE_LINE_103_TEMPERATURE : 36|12@1+ (0.0625,-106) [-106|150] "C" Vector__XXX
 SG_ SENSE_LINE_99_TEMPERATURE : 48|12@1+ (0.0625,-106) [-106|150] "C" Vector__XXX

BO_ 1825 BMS_TEMPERATURES_108_120: 8 BMS
 SG_ SENSE_LINE_109_TEMPERATURE : 0|12@1+ (0.0625,-106) [-106|150] "C" Vector__XXX
 SG_ SENSE_LINE_113_TEMPERATURE : 12|12@1+ (0.0625,-106) [-106|150] "C" Vector__XXX
 SG_ SENSE_LINE_117_TEMPERATURE : 24|12@1+ (0.0625,-106) [-106|150] "C" Vector__XXX
 SG_ SENSE_LINE_112_TEMPERATURE : 36|12@1+ (0.0625,-106) [-106|150] "C" Vector__XXX
 SG_ SENSE_LINE_116_TEMPERATURE : 48|12@1+ (0.0625,-106) [-106|150] "C" Vector__XXX

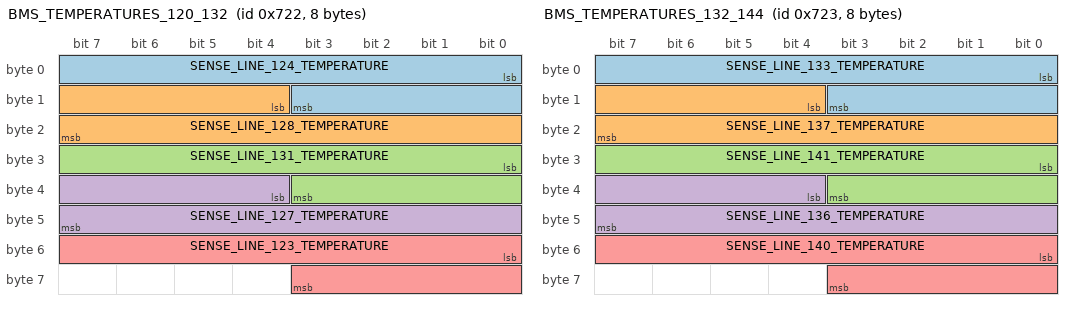
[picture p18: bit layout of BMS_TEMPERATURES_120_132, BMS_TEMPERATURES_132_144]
BO_ 1826 BMS_TEMPERATURES_120_132: 8 BMS
 SG_ SENSE_LINE_124_TEMPERATURE : 0|12@1+ (0.0625,-106) [-106|150] "C" Vector__XXX
 SG_ SENSE_LINE_128_TEMPERATURE : 12|12@1+ (0.0625,-106) [-106|150] "C" Vector__XXX
 SG_ SENSE_LINE_131_TEMPERATURE : 24|12@1+ (0.0625,-106) [-106|150] "C" Vector__XXX
 SG_ SENSE_LINE_127_TEMPERATURE : 36|12@1+ (0.0625,-106) [-106|150] "C" Vector__XXX
 SG_ SENSE_LINE_123_TEMPERATURE : 48|12@1+ (0.0625,-106) [-106|150] "C" Vector__XXX

BO_ 1827 BMS_TEMPERATURES_132_144: 8 BMS
 SG_ SENSE_LINE_133_TEMPERATURE : 0|12@1+ (0.0625,-106) [-106|150] "C" Vector__XXX
 SG_ SENSE_LINE_137_TEMPERATURE : 12|12@1+ (0.0625,-106) [-106|150] "C" Vector__XXX
 SG_ SENSE_LINE_141_TEMPERATURE : 24|12@1+ (0.0625,-106) [-106|150] "C" Vector__XXX
 SG_ SENSE_LINE_136_TEMPERATURE : 36|12@1+ (0.0625,-106) [-106|150] "C" Vector__XXX
 SG_ SENSE_LINE_140_TEMPERATURE : 48|12@1+ (0.0625,-106) [-106|150] "C" Vector__XXX

BO_ 1828 BMS_SENSE_LINE_STATUSES_0_48: 8 BMS
 SG_ SENSE_LINE_0_HI_OPEN : 0|1@1+ (1,0) [0|1] "Bool" Vector__XXX
 SG_ SENSE_LINE_1_OPEN : 1|1@1+ (1,0) [0|1] "Bool" Vector__XXX
 SG_ SENSE_LINE_2_OPEN : 2|1@1+ (1,0) [0|1] "Bool" Vector__XXX
 SG_ SENSE_LINE_3_OPEN : 3|1@1+ (1,0) [0|1] "Bool" Vector__XXX
 SG_ SENSE_LINE_4_OPEN : 4|1@1+ (1,0) [0|1] "Bool" Vector__XXX
 SG_ SENSE_LINE_5_OPEN : 5|1@1+ (1,0) [0|1] "Bool" Vector__XXX
 SG_ SENSE_LINE_6_OPEN : 6|1@1+ (1,0) [0|1] "Bool" Vector__XXX
 SG_ SENSE_LINE_7_OPEN : 7|1@1+ (1,0) [0|1] "Bool" Vector__XXX
 SG_ SENSE_LINE_8_OPEN : 8|1@1+ (1,0) [0|1] "Bool" Vector__XXX
 SG_ SENSE_LINE_9_OPEN : 9|1@1+ (1,0) [0|1] "Bool" Vector__XXX
 SG_ SENSE_LINE_10_OPEN : 10|1@1+ (1,0) [0|1] "Bool" Vector__XXX
 SG_ SENSE_LINE_11_OPEN : 11|1@1+ (1,0) [0|1] "Bool" Vector__XXX
 SG_ SENSE_LINE_12_LO_OPEN : 12|1@1+ (1,0) [0|1] "Bool" Vector__XXX
 SG_ SENSE_LINE_12_HI_OPEN : 16|1@1+ (1,0) [0|1] "Bool" Vector__XXX
 SG_ SENSE_LINE_13_OPEN : 17|1@1+ (1,0) [0|1] "Bool" Vector__XXX
 SG_ SENSE_LINE_14_OPEN : 18|1@1+ (1,0) [0|1] "Bool" Vector__XXX
 SG_ SENSE_LINE_15_OPEN : 19|1@1+ (1,0) [0|1] "Bool" Vector__XXX
 SG_ SENSE_LINE_16_OPEN : 20|1@1+ (1,0) [0|1] "Bool" Vector__XXX
 SG_ SENSE_LINE_17_OPEN : 21|1@1+ (1,0) [0|1] "Bool" Vector__XXX
 SG_ SENSE_LINE_18_OPEN : 22|1@1+ (1,0) [0|1] "Bool" Vector__XXX
 SG_ SENSE_LINE_19_OPEN : 23|1@1+ (1,0) [0|1] "Bool" Vector__XXX
 SG_ SENSE_LINE_20_OPEN : 24|1@1+ (1,0) [0|1] "Bool" Vector__XXX
 SG_ SENSE_LINE_21_OPEN : 25|1@1+ (1,0) [0|1] "Bool" Vector__XXX
 SG_ SENSE_LINE_22_OPEN : 26|1@1+ (1,0) [0|1] "Bool" Vector__XXX
 SG_ SENSE_LINE_23_OPEN : 27|1@1+ (1,0) [0|1] "Bool" Vector__XXX
 SG_ SENSE_LINE_24_LO_OPEN : 28|1@1+ (1,0) [0|1] "Bool" Vector__XXX
 SG_ SENSE_LINE_24_HI_OPEN : 32|1@1+ (1,0) [0|1] "Bool" Vector__XXX
 SG_ SENSE_LINE_25_OPEN : 33|1@1+ (1,0) [0|1] "Bool" Vector__XXX
 SG_ SENSE_LINE_26_OPEN : 34|1@1+ (1,0) [0|1] "Bool" Vector__XXX
 SG_ SENSE_LINE_27_OPEN : 35|1@1+ (1,0) [0|1] "Bool" Vector__XXX
 SG_ SENSE_LINE_28_OPEN : 36|1@1+ (1,0) [0|1] "Bool" Vector__XXX
 SG_ SENSE_LINE_29_OPEN : 37|1@1+ (1,0) [0|1] "Bool" Vector__XXX
 SG_ SENSE_LINE_30_OPEN : 38|1@1+ (1,0) [0|1] "Bool" Vector__XXX
 SG_ SENSE_LINE_31_OPEN : 39|1@1+ (1,0) [0|1] "Bool" Vector__XXX
 SG_ SENSE_LINE_32_OPEN : 40|1@1+ (1,0) [0|1] "Bool" Vector__XXX
 SG_ SENSE_LINE_33_OPEN : 41|1@1+ (1,0) [0|1] "Bool" Vector__XXX
 SG_ SENSE_LINE_34_OPEN : 42|1@1+ (1,0) [0|1] "Bool" Vector__XXX
 SG_ SENSE_LINE_35_OPEN : 43|1@1+ (1,0) [0|1] "Bool" Vector__XXX
 SG_ SENSE_LINE_36_LO_OPEN : 44|1@1+ (1,0) [0|1] "Bool" Vector__XXX
 SG_ SENSE_LINE_36_HI_OPEN : 48|1@1+ (1,0) [0|1] "Bool" Vector__XXX
 SG_ SENSE_LINE_37_OPEN : 49|1@1+ (1,0) [0|1] "Bool" Vector__XXX
 SG_ SENSE_LINE_38_OPEN : 50|1@1+ (1,0) [0|1] "Bool" Vector__XXX
 SG_ SENSE_LINE_39_OPEN : 51|1@1+ (1,0) [0|1] "Bool" Vector__XXX
 SG_ SENSE_LINE_40_OPEN : 52|1@1+ (1,0) [0|1] "Bool" Vector__XXX
 SG_ SENSE_LINE_41_OPEN : 53|1@1+ (1,0) [0|1] "Bool" Vector__XXX
 SG_ SENSE_LINE_42_OPEN : 54|1@1+ (1,0) [0|1] "Bool" Vector__XXX
 SG_ SENSE_LINE_43_OPEN : 55|1@1+ (1,0) [0|1] "Bool" Vector__XXX
 SG_ SENSE_LINE_44_OPEN : 56|1@1+ (1,0) [0|1] "Bool" Vector__XXX
 SG_ SENSE_LINE_45_OPEN : 57|1@1+ (1,0) [0|1] "Bool" Vector__XXX
 SG_ SENSE_LINE_46_OPEN : 58|1@1+ (1,0) [0|1] "Bool" Vector__XXX
 SG_ SENSE_LINE_47_OPEN : 59|1@1+ (1,0) [0|1] "Bool" Vector__XXX
 SG_ SENSE_LINE_48_LO_OPEN : 60|1@1+ (1,0) [0|1] "Bool" Vector__XXX

BO_ 1829 BMS_SENSE_LINE_STATUSES_48_96: 8 BMS
 SG_ SENSE_LINE_48_HI_OPEN : 0|1@1+ (1,0) [0|1] "Bool" Vector__XXX
 SG_ SENSE_LINE_49_OPEN : 1|1@1+ (1,0) [0|1] "Bool" Vector__XXX
 SG_ SENSE_LINE_50_OPEN : 2|1@1+ (1,0) [0|1] "Bool" Vector__XXX
 SG_ SENSE_LINE_51_OPEN : 3|1@1+ (1,0) [0|1] "Bool" Vector__XXX
 SG_ SENSE_LINE_52_OPEN : 4|1@1+ (1,0) [0|1] "Bool" Vector__XXX
 SG_ SENSE_LINE_53_OPEN : 5|1@1+ (1,0) [0|1] "Bool" Vector__XXX
 SG_ SENSE_LINE_54_OPEN : 6|1@1+ (1,0) [0|1] "Bool" Vector__XXX
 SG_ SENSE_LINE_55_OPEN : 7|1@1+ (1,0) [0|1] "Bool" Vector__XXX
 SG_ SENSE_LINE_56_OPEN : 8|1@1+ (1,0) [0|1] "Bool" Vector__XXX
 SG_ SENSE_LINE_57_OPEN : 9|1@1+ (1,0) [0|1] "Bool" Vector__XXX
 SG_ SENSE_LINE_58_OPEN : 10|1@1+ (1,0) [0|1] "Bool" Vector__XXX
 SG_ SENSE_LINE_59_OPEN : 11|1@1+ (1,0) [0|1] "Bool" Vector__XXX
 SG_ SENSE_LINE_60_LO_OPEN : 12|1@1+ (1,0) [0|1] "Bool" Vector__XXX
 SG_ SENSE_LINE_60_HI_OPEN : 16|1@1+ (1,0) [0|1] "Bool" Vector__XXX
 SG_ SENSE_LINE_61_OPEN : 17|1@1+ (1,0) [0|1] "Bool" Vector__XXX
 SG_ SENSE_LINE_62_OPEN : 18|1@1+ (1,0) [0|1] "Bool" Vector__XXX
 SG_ SENSE_LINE_63_OPEN : 19|1@1+ (1,0) [0|1] "Bool" Vector__XXX
 SG_ SENSE_LINE_64_OPEN : 20|1@1+ (1,0) [0|1] "Bool" Vector__XXX
 SG_ SENSE_LINE_65_OPEN : 21|1@1+ (1,0) [0|1] "Bool" Vector__XXX
 SG_ SENSE_LINE_66_OPEN : 22|1@1+ (1,0) [0|1] "Bool" Vector__XXX
 SG_ SENSE_LINE_67_OPEN : 23|1@1+ (1,0) [0|1] "Bool" Vector__XXX
 SG_ SENSE_LINE_68_OPEN : 24|1@1+ (1,0) [0|1] "Bool" Vector__XXX
 SG_ SENSE_LINE_69_OPEN : 25|1@1+ (1,0) [0|1] "Bool" Vector__XXX
 SG_ SENSE_LINE_70_OPEN : 26|1@1+ (1,0) [0|1] "Bool" Vector__XXX
 SG_ SENSE_LINE_71_OPEN : 27|1@1+ (1,0) [0|1] "Bool" Vector__XXX
 SG_ SENSE_LINE_72_LO_OPEN : 28|1@1+ (1,0) [0|1] "Bool" Vector__XXX
 SG_ SENSE_LINE_72_HI_OPEN : 32|1@1+ (1,0) [0|1] "Bool" Vector__XXX
 SG_ SENSE_LINE_73_OPEN : 33|1@1+ (1,0) [0|1] "Bool" Vector__XXX
 SG_ SENSE_LINE_74_OPEN : 34|1@1+ (1,0) [0|1] "Bool" Vector__XXX
 SG_ SENSE_LINE_75_OPEN : 35|1@1+ (1,0) [0|1] "Bool" Vector__XXX
 SG_ SENSE_LINE_76_OPEN : 36|1@1+ (1,0) [0|1] "Bool" Vector__XXX
 SG_ SENSE_LINE_77_OPEN : 37|1@1+ (1,0) [0|1] "Bool" Vector__XXX
 SG_ SENSE_LINE_78_OPEN : 38|1@1+ (1,0) [0|1] "Bool" Vector__XXX
 SG_ SENSE_LINE_79_OPEN : 39|1@1+ (1,0) [0|1] "Bool" Vector__XXX
 SG_ SENSE_LINE_80_OPEN : 40|1@1+ (1,0) [0|1] "Bool" Vector__XXX
 SG_ SENSE_LINE_81_OPEN : 41|1@1+ (1,0) [0|1] "Bool" Vector__XXX
 SG_ SENSE_LINE_82_OPEN : 42|1@1+ (1,0) [0|1] "Bool" Vector__XXX
 SG_ SENSE_LINE_83_OPEN : 43|1@1+ (1,0) [0|1] "Bool" Vector__XXX
 SG_ SENSE_LINE_84_LO_OPEN : 44|1@1+ (1,0) [0|1] "Bool" Vector__XXX
 SG_ SENSE_LINE_84_HI_OPEN : 48|1@1+ (1,0) [0|1] "Bool" Vector__XXX
 SG_ SENSE_LINE_85_OPEN : 49|1@1+ (1,0) [0|1] "Bool" Vector__XXX
 SG_ SENSE_LINE_86_OPEN : 50|1@1+ (1,0) [0|1] "Bool" Vector__XXX
 SG_ SENSE_LINE_87_OPEN : 51|1@1+ (1,0) [0|1] "Bool" Vector__XXX
 SG_ SENSE_LINE_88_OPEN : 52|1@1+ (1,0) [0|1] "Bool" Vector__XXX
 SG_ SENSE_LINE_89_OPEN : 53|1@1+ (1,0) [0|1] "Bool" Vector__XXX
 SG_ SENSE_LINE_90_OPEN : 54|1@1+ (1,0) [0|1] "Bool" Vector__XXX
 SG_ SENSE_LINE_91_OPEN : 55|1@1+ (1,0) [0|1] "Bool" Vector__XXX
 SG_ SENSE_LINE_92_OPEN : 56|1@1+ (1,0) [0|1] "Bool" Vector__XXX
 SG_ SENSE_LINE_93_OPEN : 57|1@1+ (1,0) [0|1] "Bool" Vector__XXX
 SG_ SENSE_LINE_94_OPEN : 58|1@1+ (1,0) [0|1] "Bool" Vector__XXX
 SG_ SENSE_LINE_95_OPEN : 59|1@1+ (1,0) [0|1] "Bool" Vector__XXX
 SG_ SENSE_LINE_96_LO_OPEN : 60|1@1+ (1,0) [0|1] "Bool" Vector__XXX

BO_ 1830 BMS_SENSE_LINE_STATUSES_96_144: 8 BMS
 SG_ SENSE_LINE_96_HI_OPEN : 0|1@1+ (1,0) [0|1] "Bool" Vector__XXX
 SG_ SENSE_LINE_97_OPEN : 1|1@1+ (1,0) [0|1] "Bool" Vector__XXX
 SG_ SENSE_LINE_98_OPEN : 2|1@1+ (1,0) [0|1] "Bool" Vector__XXX
 SG_ SENSE_LINE_99_OPEN : 3|1@1+ (1,0) [0|1] "Bool" Vector__XXX
 SG_ SENSE_LINE_100_OPEN : 4|1@1+ (1,0) [0|1] "Bool" Vector__XXX
 SG_ SENSE_LINE_101_OPEN : 5|1@1+ (1,0) [0|1] "Bool" Vector__XXX
 SG_ SENSE_LINE_102_OPEN : 6|1@1+ (1,0) [0|1] "Bool" Vector__XXX
 SG_ SENSE_LINE_103_OPEN : 7|1@1+ (1,0) [0|1] "Bool" Vector__XXX
 SG_ SENSE_LINE_104_OPEN : 8|1@1+ (1,0) [0|1] "Bool" Vector__XXX
 SG_ SENSE_LINE_105_OPEN : 9|1@1+ (1,0) [0|1] "Bool" Vector__XXX
 SG_ SENSE_LINE_106_OPEN : 10|1@1+ (1,0) [0|1] "Bool" Vector__XXX
 SG_ SENSE_LINE_107_OPEN : 11|1@1+ (1,0) [0|1] "Bool" Vector__XXX
 SG_ SENSE_LINE_108_LO_OPEN : 12|1@1+ (1,0) [0|1] "Bool" Vector__XXX
 SG_ SENSE_LINE_108_HI_OPEN : 16|1@1+ (1,0) [0|1] "Bool" Vector__XXX
 SG_ SENSE_LINE_109_OPEN : 17|1@1+ (1,0) [0|1] "Bool" Vector__XXX
 SG_ SENSE_LINE_110_OPEN : 18|1@1+ (1,0) [0|1] "Bool" Vector__XXX
 SG_ SENSE_LINE_111_OPEN : 19|1@1+ (1,0) [0|1] "Bool" Vector__XXX
 SG_ SENSE_LINE_112_OPEN : 20|1@1+ (1,0) [0|1] "Bool" Vector__XXX
 SG_ SENSE_LINE_113_OPEN : 21|1@1+ (1,0) [0|1] "Bool" Vector__XXX
 SG_ SENSE_LINE_114_OPEN : 22|1@1+ (1,0) [0|1] "Bool" Vector__XXX
 SG_ SENSE_LINE_115_OPEN : 23|1@1+ (1,0) [0|1] "Bool" Vector__XXX
 SG_ SENSE_LINE_116_OPEN : 24|1@1+ (1,0) [0|1] "Bool" Vector__XXX
 SG_ SENSE_LINE_117_OPEN : 25|1@1+ (1,0) [0|1] "Bool" Vector__XXX
 SG_ SENSE_LINE_118_OPEN : 26|1@1+ (1,0) [0|1] "Bool" Vector__XXX
 SG_ SENSE_LINE_119_OPEN : 27|1@1+ (1,0) [0|1] "Bool" Vector__XXX
 SG_ SENSE_LINE_120_LO_OPEN : 28|1@1+ (1,0) [0|1] "Bool" Vector__XXX
 SG_ SENSE_LINE_120_HI_OPEN : 32|1@1+ (1,0) [0|1] "Bool" Vector__XXX
 SG_ SENSE_LINE_121_OPEN : 33|1@1+ (1,0) [0|1] "Bool" Vector__XXX
 SG_ SENSE_LINE_122_OPEN : 34|1@1+ (1,0) [0|1] "Bool" Vector__XXX
 SG_ SENSE_LINE_123_OPEN : 35|1@1+ (1,0) [0|1] "Bool" Vector__XXX
 SG_ SENSE_LINE_124_OPEN : 36|1@1+ (1,0) [0|1] "Bool" Vector__XXX
 SG_ SENSE_LINE_125_OPEN : 37|1@1+ (1,0) [0|1] "Bool" Vector__XXX
 SG_ SENSE_LINE_126_OPEN : 38|1@1+ (1,0) [0|1] "Bool" Vector__XXX
 SG_ SENSE_LINE_127_OPEN : 39|1@1+ (1,0) [0|1] "Bool" Vector__XXX
 SG_ SENSE_LINE_128_OPEN : 40|1@1+ (1,0) [0|1] "Bool" Vector__XXX
 SG_ SENSE_LINE_129_OPEN : 41|1@1+ (1,0) [0|1] "Bool" Vector__XXX
 SG_ SENSE_LINE_130_OPEN : 42|1@1+ (1,0) [0|1] "Bool" Vector__XXX
 SG_ SENSE_LINE_131_OPEN : 43|1@1+ (1,0) [0|1] "Bool" Vector__XXX
 SG_ SENSE_LINE_132_LO_OPEN : 44|1@1+ (1,0) [0|1] "Bool" Vector__XXX
 SG_ SENSE_LINE_132_HI_OPEN : 48|1@1+ (1,0) [0|1] "Bool" Vector__XXX
 SG_ SENSE_LINE_133_OPEN : 49|1@1+ (1,0) [0|1] "Bool" Vector__XXX
 SG_ SENSE_LINE_134_OPEN : 50|1@1+ (1,0) [0|1] "Bool" Vector__XXX
 SG_ SENSE_LINE_135_OPEN : 51|1@1+ (1,0) [0|1] "Bool" Vector__XXX
 SG_ SENSE_LINE_136_OPEN : 52|1@1+ (1,0) [0|1] "Bool" Vector__XXX
 SG_ SENSE_LINE_137_OPEN : 53|1@1+ (1,0) [0|1] "Bool" Vector__XXX
 SG_ SENSE_LINE_138_OPEN : 54|1@1+ (1,0) [0|1] "Bool" Vector__XXX
 SG_ SENSE_LINE_139_OPEN : 55|1@1+ (1,0) [0|1] "Bool" Vector__XXX
 SG_ SENSE_LINE_140_OPEN : 56|1@1+ (1,0) [0|1] "Bool" Vector__XXX
 SG_ SENSE_LINE_141_OPEN : 57|1@1+ (1,0) [0|1] "Bool" Vector__XXX
 SG_ SENSE_LINE_142_OPEN : 58|1@1+ (1,0) [0|1] "Bool" Vector__XXX
 SG_ SENSE_LINE_143_OPEN : 59|1@1+ (1,0) [0|1] "Bool" Vector__XXX
 SG_ SENSE_LINE_144_LO_OPEN : 60|1@1+ (1,0) [0|1] "Bool" Vector__XXX

BO_ 1833 BMS_CELL_BALANCINGS_0_47: 8 BMS
 SG_ CELL_BALANCING_0 : 0|1@1+ (1,0) [0|1] "Bool" Vector__XXX
 SG_ CELL_BALANCING_1 : 1|1@1+ (1,0) [0|1] "Bool" Vector__XXX
 SG_ CELL_BALANCING_2 : 2|1@1+ (1,0) [0|1] "Bool" Vector__XXX
 SG_ CELL_BALANCING_3 : 3|1@1+ (1,0) [0|1] "Bool" Vector__XXX
 SG_ CELL_BALANCING_4 : 4|1@1+ (1,0) [0|1] "Bool" Vector__XXX
 SG_ CELL_BALANCING_5 : 5|1@1+ (1,0) [0|1] "Bool" Vector__XXX
 SG_ CELL_BALANCING_6 : 6|1@1+ (1,0) [0|1] "Bool" Vector__XXX
 SG_ CELL_BALANCING_7 : 7|1@1+ (1,0) [0|1] "Bool" Vector__XXX
 SG_ CELL_BALANCING_8 : 8|1@1+ (1,0) [0|1] "Bool" Vector__XXX
 SG_ CELL_BALANCING_9 : 9|1@1+ (1,0) [0|1] "Bool" Vector__XXX
 SG_ CELL_BALANCING_10 : 10|1@1+ (1,0) [0|1] "Bool" Vector__XXX
 SG_ CELL_BALANCING_11 : 11|1@1+ (1,0) [0|1] "Bool" Vector__XXX
 SG_ CELL_BALANCING_12 : 16|1@1+ (1,0) [0|1] "Bool" Vector__XXX
 SG_ CELL_BALANCING_13 : 17|1@1+ (1,0) [0|1] "Bool" Vector__XXX
 SG_ CELL_BALANCING_14 : 18|1@1+ (1,0) [0|1] "Bool" Vector__XXX
 SG_ CELL_BALANCING_15 : 19|1@1+ (1,0) [0|1] "Bool" Vector__XXX
 SG_ CELL_BALANCING_16 : 20|1@1+ (1,0) [0|1] "Bool" Vector__XXX
 SG_ CELL_BALANCING_17 : 21|1@1+ (1,0) [0|1] "Bool" Vector__XXX
 SG_ CELL_BALANCING_18 : 22|1@1+ (1,0) [0|1] "Bool" Vector__XXX
 SG_ CELL_BALANCING_19 : 23|1@1+ (1,0) [0|1] "Bool" Vector__XXX
 SG_ CELL_BALANCING_20 : 24|1@1+ (1,0) [0|1] "Bool" Vector__XXX
 SG_ CELL_BALANCING_21 : 25|1@1+ (1,0) [0|1] "Bool" Vector__XXX
 SG_ CELL_BALANCING_22 : 26|1@1+ (1,0) [0|1] "Bool" Vector__XXX
 SG_ CELL_BALANCING_23 : 27|1@1+ (1,0) [0|1] "Bool" Vector__XXX
 SG_ CELL_BALANCING_24 : 32|1@1+ (1,0) [0|1] "Bool" Vector__XXX
 SG_ CELL_BALANCING_25 : 33|1@1+ (1,0) [0|1] "Bool" Vector__XXX
 SG_ CELL_BALANCING_26 : 34|1@1+ (1,0) [0|1] "Bool" Vector__XXX
 SG_ CELL_BALANCING_27 : 35|1@1+ (1,0) [0|1] "Bool" Vector__XXX
 SG_ CELL_BALANCING_28 : 36|1@1+ (1,0) [0|1] "Bool" Vector__XXX
 SG_ CELL_BALANCING_29 : 37|1@1+ (1,0) [0|1] "Bool" Vector__XXX
 SG_ CELL_BALANCING_39 : 38|1@1+ (1,0) [0|1] "Bool" Vector__XXX
 SG_ CELL_BALANCING_31 : 39|1@1+ (1,0) [0|1] "Bool" Vector__XXX
 SG_ CELL_BALANCING_32 : 40|1@1+ (1,0) [0|1] "Bool" Vector__XXX
 SG_ CELL_BALANCING_33 : 41|1@1+ (1,0) [0|1] "Bool" Vector__XXX
 SG_ CELL_BALANCING_34 : 42|1@1+ (1,0) [0|1] "Bool" Vector__XXX
 SG_ CELL_BALANCING_35 : 43|1@1+ (1,0) [0|1] "Bool" Vector__XXX
 SG_ CELL_BALANCING_36 : 48|1@1+ (1,0) [0|1] "Bool" Vector__XXX
 SG_ CELL_BALANCING_37 : 49|1@1+ (1,0) [0|1] "Bool" Vector__XXX
 SG_ CELL_BALANCING_38 : 50|1@1+ (1,0) [0|1] "Bool" Vector__XXX
 SG_ CELL_BALANCING_30 : 51|1@1+ (1,0) [0|1] "Bool" Vector__XXX
 SG_ CELL_BALANCING_40 : 52|1@1+ (1,0) [0|1] "Bool" Vector__XXX
 SG_ CELL_BALANCING_41 : 53|1@1+ (1,0) [0|1] "Bool" Vector__XXX
 SG_ CELL_BALANCING_42 : 54|1@1+ (1,0) [0|1] "Bool" Vector__XXX
 SG_ CELL_BALANCING_43 : 55|1@1+ (1,0) [0|1] "Bool" Vector__XXX
 SG_ CELL_BALANCING_44 : 56|1@1+ (1,0) [0|1] "Bool" Vector__XXX
 SG_ CELL_BALANCING_45 : 57|1@1+ (1,0) [0|1] "Bool" Vector__XXX
 SG_ CELL_BALANCING_46 : 58|1@1+ (1,0) [0|1] "Bool" Vector__XXX
 SG_ CELL_BALANCING_47 : 59|1@1+ (1,0) [0|1] "Bool" Vector__XXX

BO_ 1834 BMS_CELL_BALANCINGS_48_95: 8 BMS
 SG_ CELL_BALANCING_48 : 0|1@1+ (1,0) [0|1] "Bool" Vector__XXX
 SG_ CELL_BALANCING_49 : 1|1@1+ (1,0) [0|1] "Bool" Vector__XXX
 SG_ CELL_BALANCING_50 : 2|1@1+ (1,0) [0|1] "Bool" Vector__XXX
 SG_ CELL_BALANCING_51 : 3|1@1+ (1,0) [0|1] "Bool" Vector__XXX
 SG_ CELL_BALANCING_52 : 4|1@1+ (1,0) [0|1] "Bool" Vector__XXX
 SG_ CELL_BALANCING_53 : 5|1@1+ (1,0) [0|1] "Bool" Vector__XXX
 SG_ CELL_BALANCING_54 : 6|1@1+ (1,0) [0|1] "Bool" Vector__XXX
 SG_ CELL_BALANCING_55 : 7|1@1+ (1,0) [0|1] "Bool" Vector__XXX
 SG_ CELL_BALANCING_56 : 8|1@1+ (1,0) [0|1] "Bool" Vector__XXX
 SG_ CELL_BALANCING_57 : 9|1@1+ (1,0) [0|1] "Bool" Vector__XXX
 SG_ CELL_BALANCING_58 : 10|1@1+ (1,0) [0|1] "Bool" Vector__XXX
 SG_ CELL_BALANCING_59 : 11|1@1+ (1,0) [0|1] "Bool" Vector__XXX
 SG_ CELL_BALANCING_60 : 16|1@1+ (1,0) [0|1] "Bool" Vector__XXX
 SG_ CELL_BALANCING_61 : 17|1@1+ (1,0) [0|1] "Bool" Vector__XXX
 SG_ CELL_BALANCING_62 : 18|1@1+ (1,0) [0|1] "Bool" Vector__XXX
 SG_ CELL_BALANCING_63 : 19|1@1+ (1,0) [0|1] "Bool" Vector__XXX
 SG_ CELL_BALANCING_64 : 20|1@1+ (1,0) [0|1] "Bool" Vector__XXX
 SG_ CELL_BALANCING_65 : 21|1@1+ (1,0) [0|1] "Bool" Vector__XXX
 SG_ CELL_BALANCING_66 : 22|1@1+ (1,0) [0|1] "Bool" Vector__XXX
 SG_ CELL_BALANCING_67 : 23|1@1+ (1,0) [0|1] "Bool" Vector__XXX
 SG_ CELL_BALANCING_68 : 24|1@1+ (1,0) [0|1] "Bool" Vector__XXX
 SG_ CELL_BALANCING_69 : 25|1@1+ (1,0) [0|1] "Bool" Vector__XXX
 SG_ CELL_BALANCING_70 : 26|1@1+ (1,0) [0|1] "Bool" Vector__XXX
 SG_ CELL_BALANCING_71 : 27|1@1+ (1,0) [0|1] "Bool" Vector__XXX
 SG_ CELL_BALANCING_72 : 32|1@1+ (1,0) [0|1] "Bool" Vector__XXX
 SG_ CELL_BALANCING_73 : 33|1@1+ (1,0) [0|1] "Bool" Vector__XXX
 SG_ CELL_BALANCING_74 : 34|1@1+ (1,0) [0|1] "Bool" Vector__XXX
 SG_ CELL_BALANCING_75 : 35|1@1+ (1,0) [0|1] "Bool" Vector__XXX
 SG_ CELL_BALANCING_76 : 36|1@1+ (1,0) [0|1] "Bool" Vector__XXX
 SG_ CELL_BALANCING_77 : 37|1@1+ (1,0) [0|1] "Bool" Vector__XXX
 SG_ CELL_BALANCING_78 : 38|1@1+ (1,0) [0|1] "Bool" Vector__XXX
 SG_ CELL_BALANCING_79 : 39|1@1+ (1,0) [0|1] "Bool" Vector__XXX
 SG_ CELL_BALANCING_80 : 40|1@1+ (1,0) [0|1] "Bool" Vector__XXX
 SG_ CELL_BALANCING_81 : 41|1@1+ (1,0) [0|1] "Bool" Vector__XXX
 SG_ CELL_BALANCING_82 : 42|1@1+ (1,0) [0|1] "Bool" Vector__XXX
 SG_ CELL_BALANCING_83 : 43|1@1+ (1,0) [0|1] "Bool" Vector__XXX
 SG_ CELL_BALANCING_84 : 48|1@1+ (1,0) [0|1] "Bool" Vector__XXX
 SG_ CELL_BALANCING_85 : 49|1@1+ (1,0) [0|1] "Bool" Vector__XXX
 SG_ CELL_BALANCING_86 : 50|1@1+ (1,0) [0|1] "Bool" Vector__XXX
 SG_ CELL_BALANCING_87 : 51|1@1+ (1,0) [0|1] "Bool" Vector__XXX
 SG_ CELL_BALANCING_88 : 52|1@1+ (1,0) [0|1] "Bool" Vector__XXX
 SG_ CELL_BALANCING_89 : 53|1@1+ (1,0) [0|1] "Bool" Vector__XXX
 SG_ CELL_BALANCING_90 : 54|1@1+ (1,0) [0|1] "Bool" Vector__XXX
 SG_ CELL_BALANCING_91 : 55|1@1+ (1,0) [0|1] "Bool" Vector__XXX
 SG_ CELL_BALANCING_92 : 56|1@1+ (1,0) [0|1] "Bool" Vector__XXX
 SG_ CELL_BALANCING_93 : 57|1@1+ (1,0) [0|1] "Bool" Vector__XXX
 SG_ CELL_BALANCING_94 : 58|1@1+ (1,0) [0|1] "Bool" Vector__XXX
 SG_ CELL_BALANCING_95 : 59|1@1+ (1,0) [0|1] "Bool" Vector__XXX

BO_ 1835 BMS_CELL_BALANCINGS_96_143: 8 BMS
 SG_ CELL_BALANCING_96 : 0|1@1+ (1,0) [0|1] "Bool" Vector__XXX
 SG_ CELL_BALANCING_97 : 1|1@1+ (1,0) [0|1] "Bool" Vector__XXX
 SG_ CELL_BALANCING_98 : 2|1@1+ (1,0) [0|1] "Bool" Vector__XXX
 SG_ CELL_BALANCING_99 : 3|1@1+ (1,0) [0|1] "Bool" Vector__XXX
 SG_ CELL_BALANCING_100 : 4|1@1+ (1,0) [0|1] "Bool" Vector__XXX
 SG_ CELL_BALANCING_101 : 5|1@1+ (1,0) [0|1] "Bool" Vector__XXX
 SG_ CELL_BALANCING_102 : 6|1@1+ (1,0) [0|1] "Bool" Vector__XXX
 SG_ CELL_BALANCING_103 : 7|1@1+ (1,0) [0|1] "Bool" Vector__XXX
 SG_ CELL_BALANCING_104 : 8|1@1+ (1,0) [0|1] "Bool" Vector__XXX
 SG_ CELL_BALANCING_105 : 9|1@1+ (1,0) [0|1] "Bool" Vector__XXX
 SG_ CELL_BALANCING_106 : 10|1@1+ (1,0) [0|1] "Bool" Vector__XXX
 SG_ CELL_BALANCING_107 : 11|1@1+ (1,0) [0|1] "Bool" Vector__XXX
 SG_ CELL_BALANCING_108 : 16|1@1+ (1,0) [0|1] "Bool" Vector__XXX
 SG_ CELL_BALANCING_109 : 17|1@1+ (1,0) [0|1] "Bool" Vector__XXX
 SG_ CELL_BALANCING_110 : 18|1@1+ (1,0) [0|1] "Bool" Vector__XXX
 SG_ CELL_BALANCING_111 : 19|1@1+ (1,0) [0|1] "Bool" Vector__XXX
 SG_ CELL_BALANCING_112 : 20|1@1+ (1,0) [0|1] "Bool" Vector__XXX
 SG_ CELL_BALANCING_113 : 21|1@1+ (1,0) [0|1] "Bool" Vector__XXX
 SG_ CELL_BALANCING_114 : 22|1@1+ (1,0) [0|1] "Bool" Vector__XXX
 SG_ CELL_BALANCING_115 : 23|1@1+ (1,0) [0|1] "Bool" Vector__XXX
 SG_ CELL_BALANCING_116 : 24|1@1+ (1,0) [0|1] "Bool" Vector__XXX
 SG_ CELL_BALANCING_117 : 25|1@1+ (1,0) [0|1] "Bool" Vector__XXX
 SG_ CELL_BALANCING_118 : 26|1@1+ (1,0) [0|1] "Bool" Vector__XXX
 SG_ CELL_BALANCING_119 : 27|1@1+ (1,0) [0|1] "Bool" Vector__XXX
 SG_ CELL_BALANCING_120 : 32|1@1+ (1,0) [0|1] "Bool" Vector__XXX
 SG_ CELL_BALANCING_121 : 33|1@1+ (1,0) [0|1] "Bool" Vector__XXX
 SG_ CELL_BALANCING_122 : 34|1@1+ (1,0) [0|1] "Bool" Vector__XXX
 SG_ CELL_BALANCING_123 : 35|1@1+ (1,0) [0|1] "Bool" Vector__XXX
 SG_ CELL_BALANCING_124 : 36|1@1+ (1,0) [0|1] "Bool" Vector__XXX
 SG_ CELL_BALANCING_125 : 37|1@1+ (1,0) [0|1] "Bool" Vector__XXX
 SG_ CELL_BALANCING_126 : 38|1@1+ (1,0) [0|1] "Bool" Vector__XXX
 SG_ CELL_BALANCING_127 : 39|1@1+ (1,0) [0|1] "Bool" Vector__XXX
 SG_ CELL_BALANCING_128 : 40|1@1+ (1,0) [0|1] "Bool" Vector__XXX
 SG_ CELL_BALANCING_129 : 41|1@1+ (1,0) [0|1] "Bool" Vector__XXX
 SG_ CELL_BALANCING_130 : 42|1@1+ (1,0) [0|1] "Bool" Vector__XXX
 SG_ CELL_BALANCING_131 : 43|1@1+ (1,0) [0|1] "Bool" Vector__XXX
 SG_ CELL_BALANCING_132 : 48|1@1+ (1,0) [0|1] "Bool" Vector__XXX
 SG_ CELL_BALANCING_133 : 49|1@1+ (1,0) [0|1] "Bool" Vector__XXX
 SG_ CELL_BALANCING_134 : 50|1@1+ (1,0) [0|1] "Bool" Vector__XXX
 SG_ CELL_BALANCING_135 : 51|1@1+ (1,0) [0|1] "Bool" Vector__XXX
 SG_ CELL_BALANCING_136 : 52|1@1+ (1,0) [0|1] "Bool" Vector__XXX
 SG_ CELL_BALANCING_137 : 53|1@1+ (1,0) [0|1] "Bool" Vector__XXX
 SG_ CELL_BALANCING_138 : 54|1@1+ (1,0) [0|1] "Bool" Vector__XXX
 SG_ CELL_BALANCING_139 : 55|1@1+ (1,0) [0|1] "Bool" Vector__XXX
 SG_ CELL_BALANCING_140 : 56|1@1+ (1,0) [0|1] "Bool" Vector__XXX
 SG_ CELL_BALANCING_141 : 57|1@1+ (1,0) [0|1] "Bool" Vector__XXX
 SG_ CELL_BALANCING_142 : 58|1@1+ (1,0) [0|1] "Bool" Vector__XXX
 SG_ CELL_BALANCING_143 : 59|1@1+ (1,0) [0|1] "Bool" Vector__XXX

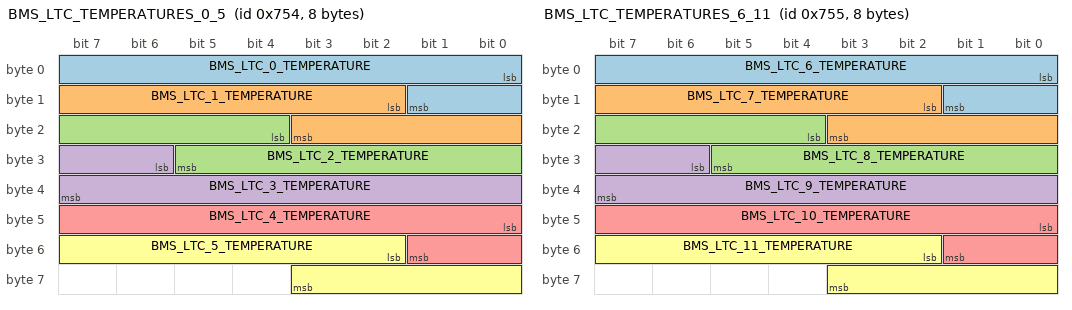
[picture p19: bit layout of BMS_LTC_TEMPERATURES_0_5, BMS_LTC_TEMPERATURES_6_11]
BO_ 1876 BMS_LTC_TEMPERATURES_0_5: 8 BMS
 SG_ BMS_LTC_0_TEMPERATURE : 0|10@1+ (0.125,-28) [-28|100] "C" Vector__XXX
 SG_ BMS_LTC_1_TEMPERATURE : 10|10@1+ (0.125,-28) [-28|100] "C" Vector__XXX
 SG_ BMS_LTC_2_TEMPERATURE : 20|10@1+ (0.125,-28) [-28|100] "C" Vector__XXX
 SG_ BMS_LTC_3_TEMPERATURE : 30|10@1+ (0.125,-28) [-28|100] "C" Vector__XXX
 SG_ BMS_LTC_4_TEMPERATURE : 40|10@1+ (0.125,-28) [-28|100] "C" Vector__XXX
 SG_ BMS_LTC_5_TEMPERATURE : 50|10@1+ (0.125,-28) [-28|100] "C" Vector__XXX

BO_ 1877 BMS_LTC_TEMPERATURES_6_11: 8 BMS
 SG_ BMS_LTC_6_TEMPERATURE : 0|10@1+ (0.125,-28) [-28|100] "C" Vector__XXX
 SG_ BMS_LTC_7_TEMPERATURE : 10|10@1+ (0.125,-28) [-28|100] "C" Vector__XXX
 SG_ BMS_LTC_8_TEMPERATURE : 20|10@1+ (0.125,-28) [-28|100] "C" Vector__XXX
 SG_ BMS_LTC_9_TEMPERATURE : 30|10@1+ (0.125,-28) [-28|100] "C" Vector__XXX
 SG_ BMS_LTC_10_TEMPERATURE : 40|10@1+ (0.125,-28) [-28|100] "C" Vector__XXX
 SG_ BMS_LTC_11_TEMPERATURE : 50|10@1+ (0.125,-28) [-28|100] "C" Vector__XXX

BA_DEF_  "BusType" STRING ;
BA_DEF_DEF_  "BusType" "CAN";

CM_ SG_ 1012 CHARGER_OPERATING_MODE "Must be 0.";
